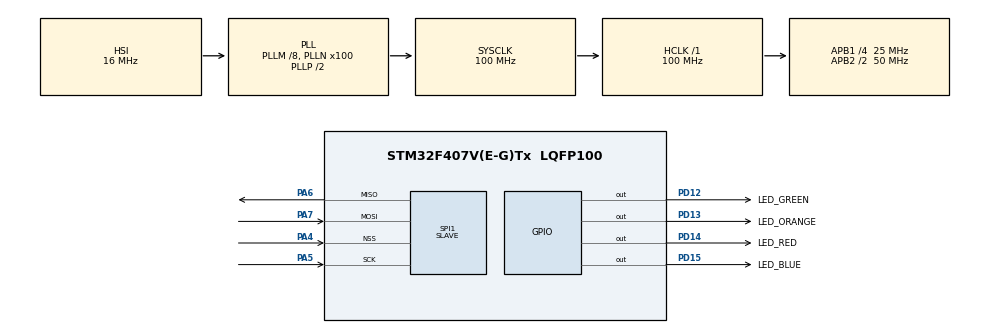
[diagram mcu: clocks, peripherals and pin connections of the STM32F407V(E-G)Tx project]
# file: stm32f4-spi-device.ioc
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Dma.Request0=SPI1_RX
Dma.Request1=SPI1_TX
Dma.SPI1_RX.0.Direction=DMA_PERIPH_TO_MEMORY
Dma.SPI1_RX.0.FIFOMode=DMA_FIFOMODE_DISABLE
Dma.SPI1_RX.0.Instance=DMA2_Stream0
Dma.SPI1_RX.0.MemDataAlignment=DMA_MDATAALIGN_BYTE
Dma.SPI1_RX.0.MemInc=DMA_MINC_ENABLE
Dma.SPI1_RX.0.Mode=DMA_NORMAL
Dma.SPI1_RX.0.PeriphDataAlignment=DMA_PDATAALIGN_BYTE
Dma.SPI1_RX.0.PeriphInc=DMA_PINC_DISABLE
Dma.SPI1_RX.0.Priority=DMA_PRIORITY_LOW
Dma.SPI1_TX.1.Direction=DMA_MEMORY_TO_PERIPH
Dma.SPI1_TX.1.FIFOMode=DMA_FIFOMODE_DISABLE
Dma.SPI1_TX.1.Instance=DMA2_Stream3
Dma.SPI1_TX.1.MemDataAlignment=DMA_MDATAALIGN_BYTE
Dma.SPI1_TX.1.MemInc=DMA_MINC_ENABLE
Dma.SPI1_TX.1.Mode=DMA_NORMAL
Dma.SPI1_TX.1.PeriphDataAlignment=DMA_PDATAALIGN_BYTE
Dma.SPI1_TX.1.PeriphInc=DMA_PINC_DISABLE
Dma.SPI1_TX.1.Priority=DMA_PRIORITY_LOW
Mcu.Family=STM32F4
Mcu.Name=STM32F407V(E-G)Tx
Mcu.Package=LQFP100
NVIC.DMA2_Stream0_IRQn=true\:5\:0\:true\:false\:true\:false\:true
NVIC.DMA2_Stream3_IRQn=true\:5\:0\:true\:false\:true\:false\:true
NVIC.PriorityGroup=NVIC_PRIORITYGROUP_4
NVIC.TIM5_IRQn=true\:0\:0\:false\:false\:true\:false\:true
NVIC.TimeBase=TIM5_IRQn
NVIC.TimeBaseIP=TIM5
PA4.Mode=NSS_Signal_Hard_Input
PA4.Signal=SPI1_NSS
PA5.Mode=Full_Duplex_Slave
PA5.Signal=SPI1_SCK
PA6.Mode=Full_Duplex_Slave
PA6.Signal=SPI1_MISO
PA7.Mode=Full_Duplex_Slave
PA7.Signal=SPI1_MOSI
PD12.GPIO_Label=LED_GREEN
PD12.Signal=GPIO_Output
PD13.GPIO_Label=LED_ORANGE
PD13.Signal=GPIO_Output
PD14.GPIO_Label=LED_RED
PD14.Signal=GPIO_Output
PD15.GPIO_Label=LED_BLUE
PD15.Signal=GPIO_Output
ProjectManager.HeapSize=0x200
ProjectManager.StackSize=0x400
ProjectManager.TargetToolchain=Makefile
RCC.48MHZClocksFreq_Value=50000000
RCC.AHBFreq_Value=100000000
RCC.APB1CLKDivider=RCC_HCLK_DIV4
RCC.APB1Freq_Value=25000000
RCC.APB1TimFreq_Value=50000000
RCC.APB2CLKDivider=RCC_HCLK_DIV2
RCC.APB2Freq_Value=50000000
RCC.APB2TimFreq_Value=100000000
RCC.CortexFreq_Value=100000000
RCC.HCLKFreq_Value=100000000
RCC.HSE_VALUE=25000000
RCC.HSI_VALUE=16000000
RCC.LSE_VALUE=32768
RCC.PLLM=8
RCC.PLLN=100
RCC.SYSCLKFreq_VALUE=100000000
RCC.SYSCLKSource=RCC_SYSCLKSOURCE_PLLCLK
RCC.VCOOutputFreq_Value=200000000
SPI1.Direction=SPI_DIRECTION_2LINES
SPI1.Mode=SPI_MODE_SLAVE
SPI1.VirtualNSS=VM_NSSHARD
SPI1.VirtualType=VM_SLAVE
VP_SYS_VS_tim5.Mode=TIM5
board=custom

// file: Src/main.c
/* USER CODE BEGIN Header */
/**
  ******************************************************************************
  * @file           : main.c
  * @brief          : Main program body
  ******************************************************************************
  * @attention
  *
  * <h2><center>&copy; Copyright (c) 2020 STMicroelectronics.
  * All rights reserved.</center></h2>
  *
  * This software component is licensed by ST under BSD 3-Clause license,
  * the "License"; You may not use this file except in compliance with the
  * License. You may obtain a copy of the License at:
  *                        opensource.org/licenses/BSD-3-Clause
  *
  ******************************************************************************
  */
/* USER CODE END Header */
#include "main.h"
#include "dma.h"
#include "spi.h"
#include "gpio.h"

/* USER CODE BEGIN Includes */
#include "FreeRTOS.h"
#include "task.h"
#include "comms.h"
/* USER CODE END Includes */

/* USER CODE BEGIN PD */
#define PRIORITY_BLINKY_TASK  ( tskIDLE_PRIORITY + 1UL )
#define PRIORITY_COMMS_TASK  ( tskIDLE_PRIORITY + 2UL )
/* USER CODE END PD */

void SystemClock_Config(void);
/* USER CODE BEGIN PFP */
void blinky_task(void *pvParameters);
/* USER CODE END PFP */

int main(void)
{

  /* MCU Configuration--------------------------------------------------------*/

  /* Reset of all peripherals, Initializes the Flash interface and the Systick. */
  HAL_Init();

  /* Configure the system clock */
  SystemClock_Config();

  /* Initialize all configured peripherals */
  MX_GPIO_Init();
  MX_DMA_Init();
  MX_SPI1_Init();
  /* USER CODE BEGIN 2 */

  xTaskCreate(blinky_task, "blinky", 100, NULL, PRIORITY_BLINKY_TASK, (TaskHandle_t *)NULL);
  xTaskCreate(comms_handler_task, "comms", 100, NULL, PRIORITY_COMMS_TASK, (TaskHandle_t *)NULL);

  vTaskStartScheduler();

  /* USER CODE END 2 */

  /* Infinite loop */
  while (1)
  {

  }
}

void SystemClock_Config(void)
{
  RCC_OscInitTypeDef RCC_OscInitStruct = {0};
  RCC_ClkInitTypeDef RCC_ClkInitStruct = {0};

  /** Configure the main internal regulator output voltage
  */
  __HAL_RCC_PWR_CLK_ENABLE();
  __HAL_PWR_VOLTAGESCALING_CONFIG(PWR_REGULATOR_VOLTAGE_SCALE1);
  /** Initializes the RCC Oscillators according to the specified parameters
  * in the RCC_OscInitTypeDef structure.
  */
  RCC_OscInitStruct.OscillatorType = RCC_OSCILLATORTYPE_HSI;
  RCC_OscInitStruct.HSIState = RCC_HSI_ON;
  RCC_OscInitStruct.HSICalibrationValue = RCC_HSICALIBRATION_DEFAULT;
  RCC_OscInitStruct.PLL.PLLState = RCC_PLL_ON;
  RCC_OscInitStruct.PLL.PLLSource = RCC_PLLSOURCE_HSI;
  RCC_OscInitStruct.PLL.PLLM = 8;
  RCC_OscInitStruct.PLL.PLLN = 100;
  RCC_OscInitStruct.PLL.PLLP = RCC_PLLP_DIV2;
  RCC_OscInitStruct.PLL.PLLQ = 4;
  if (HAL_RCC_OscConfig(&RCC_OscInitStruct) != HAL_OK)
  {
    Error_Handler();
  }
  /** Initializes the CPU, AHB and APB buses clocks
  */
  RCC_ClkInitStruct.ClockType = RCC_CLOCKTYPE_HCLK|RCC_CLOCKTYPE_SYSCLK
                              |RCC_CLOCKTYPE_PCLK1|RCC_CLOCKTYPE_PCLK2;
  RCC_ClkInitStruct.SYSCLKSource = RCC_SYSCLKSOURCE_PLLCLK;
  RCC_ClkInitStruct.AHBCLKDivider = RCC_SYSCLK_DIV1;
  RCC_ClkInitStruct.APB1CLKDivider = RCC_HCLK_DIV4;
  RCC_ClkInitStruct.APB2CLKDivider = RCC_HCLK_DIV2;

  if (HAL_RCC_ClockConfig(&RCC_ClkInitStruct, FLASH_LATENCY_3) != HAL_OK)
  {
    Error_Handler();
  }
}

/* USER CODE BEGIN 4 */
void blinky_task(void *pvParameters){
  while(1){
	HAL_GPIO_TogglePin(LED_GREEN_GPIO_Port, LED_GREEN_Pin);
	vTaskDelay(500);
  }
}
/* USER CODE END 4 */

void HAL_TIM_PeriodElapsedCallback(TIM_HandleTypeDef *htim)
{
  if (htim->Instance == TIM5) {
    HAL_IncTick();
  }
}

void Error_Handler(void)
{
}

/************************ (C) COPYRIGHT STMicroelectronics *****END OF FILE****/
